# R7FA2A1AB register map
Vendor: Renesas; Series: RA2; File version: 1.1
CPU: CM23 r1p0, little endian, MPU, no FPU, VTOR, 2 interrupt priority bits
Registers are 8-bit, read-write, reset 0x0 unless marked. A register's access mark holds for its fields unless they carry their own. Offsets are from the block's base; [hi:lo] are bit positions.

## ACMPHS0 — High,Speed Analog Comparator 0
Base 0x40085000
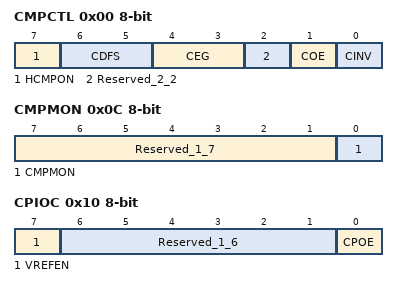
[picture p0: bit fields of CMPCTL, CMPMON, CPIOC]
0x00 CMPCTL — Comparator Control Register
  [7] HCMPON — Comparator operation control
  [6:5] CDFS — Noise filter selection
  [4:3] CEG — Selection of valid edge (Edge selector)
  [2] Reserved_2_2 — This bit is read as 0. The write value should be 0.
  [1] COE — Comparator output enable
  [0] CINV — Comparator output polarity selection
0x04 CMPSEL0 — Comparator Input Select Register
  [2:0] CMPSEL — Comparator input selection
0x08 CMPSEL1 — Comparator Reference Voltage Select Register
  [5:0] CRVS — Reference voltage selection
0x0C CMPMON ro — Comparator Output Monitor Register
  [7:1] Reserved_1_7 — These bits are read as 0000000.
  [0] CMPMON — Comparator output monitor
0x10 CPIOC — Comparator Output Control Register
  [7] VREFEN — Internal Vref enable
  [6:1] Reserved_1_6 — These bits are read as 000000. The write value should be 000000.
  [0] CPOE — Comparator output selection

## ACMPLP — Low,Power Analog Comparator
Base 0x40085E00
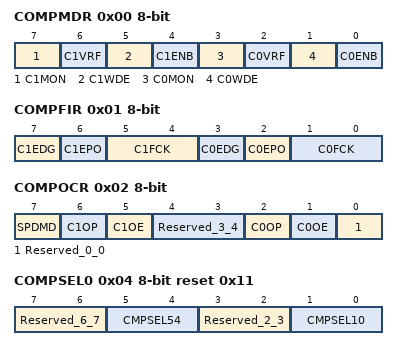
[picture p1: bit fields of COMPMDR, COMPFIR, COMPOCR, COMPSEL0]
0x00 COMPMDR — ACMPLP Mode Setting Register
  [7] C1MON — ACMPLP1 Monitor Flag
  [6] C1VRF — ACMPLP1 Reference Voltage SelectionNote1: It's effective only at the time of standard mode.IVREF0 and IVREF1 are chosen at window mode condition in spite of setting of this bit.
  [5] C1WDE — ACMPLP1 Window Function Mode Enable
  [4] C1ENB — ACMPLP1 Operation Enable
  [3] C0MON — ACMPLP0 Monitor Flag
  [2] C0VRF — ACMPLP0 Reference Voltage SelectionNote1: It's effective only at the time of standard mode.IVREF0 and IVREF1 are chosen at window mode condition in spite of setting of this bit.
  [1] C0WDE — ACMPLP0 Window Function Mode Enable
  [0] C0ENB — ACMPLP0 Operation Enable
0x01 COMPFIR — ACMPLP Filter Control Register
  [7] C1EDG — ACMPLP1 Filter Select
  [6] C1EPO — ACMPLP1 Edge Polarity Switching
  [5:4] C1FCK — ACMPLP1 Edge Detection Selection
  [3] C0EDG — ACMPLP0 Filter Select
  [2] C0EPO — ACMPLP0 Edge Polarity Switching
  [1:0] C0FCK — ACMPLP0 Edge Detection Selection
0x02 COMPOCR — ACMPLP Output Control Register
  [7] SPDMD — ACMPLP0/ACMPLP1 Speed Selection
  [6] C1OP — ACMPLP1 VCOUT Output Polarity Selection
  [5] C1OE — ACMPLP1 VCOUT Pin Output Enable
  [4:3] Reserved_3_4 — These bits are read as 00. The write value should be 00.
  [2] C0OP — ACMPLP0 VCOUT Output Polarity Selection
  [1] C0OE — ACMPLP0 VCOUT Pin Output Enable
  [0] Reserved_0_0 — This bit is read as 0. The write value should be 0.
0x04 COMPSEL0 reset 0x11 — Comparator Input Select Register
  [7:6] Reserved_6_7 — These bits are read as 00. The write value should be 00.
  [5:4] CMPSEL54 — ACMPLP1 Input (IVCMP1) Selection
  [3:2] Reserved_2_3 — These bits are read as 00. The write value should be 00.
  [1:0] CMPSEL10 — ACMPLP0 Input (IVCMP0) Selection
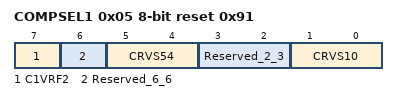
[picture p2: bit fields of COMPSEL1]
0x05 COMPSEL1 reset 0x91 — Comparator Reference voltage Select Register
  [7] C1VRF2 — ACMPLP1 Reference Voltage Selection
  [6] Reserved_6_6 — This bit is read as 0. The write value should be 0.
  [5:4] CRVS54 — ACMPLP1 Reference Voltage(IVREF1) Selection
  [3:2] Reserved_2_3 — These bits are read as 00. The write value should be 00.
  [1:0] CRVS10 — ACMPLP0 Reference Voltage (IVREF0) Selection

## TSN — Temperature Sensor
Base 0x407EC000
0x228 TSCDRL ro reset not defined — Temperature Sensor Calibration Data Register L
  [7:0] TSCDRL — The calibration data stores the lower 8 bits of the convertedvalue.
0x229 TSCDRH ro reset not defined — Temperature Sensor Calibration Data Register H
  [7:0] TSCDRH — The calibration data stores the higher 8 bits of the convertedvalue.

## DAC12 — 12-bit D/A converter
Base 0x4005E000
0x00 DADR0 16-bit — D/A Data Register 0
  [15:0] DADR — D/A Data RegisterNOTE: When DADPR.DPSEL = 0, the high,order 4 bits are fixed to 0: right justified format. When DADPR.DPSEL = 1, the low,order 4 bits are fixed to 0: left justified format.
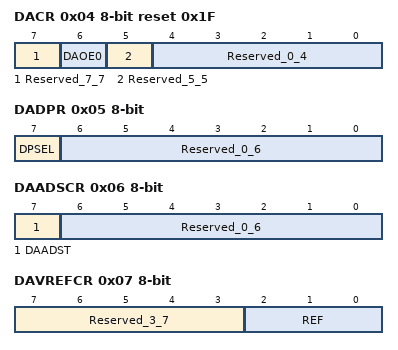
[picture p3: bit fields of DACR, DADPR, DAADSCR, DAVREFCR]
0x04 DACR reset 0x1F — D/A Control Register
  [7] Reserved_7_7 — This bit is read as 0. The write value should be 0.
  [6] DAOE0 — D/A Output Enable 0
  [5] Reserved_5_5 — This bit is read as 0. The write value should be 0.
  [4:0] Reserved_0_4 — These bits are read as 11111. The write value should be 11111.
0x05 DADPR — DADR0 Format Select Register
  [7] DPSEL — DADRm Format Select
  [6:0] Reserved_0_6 — These bits are read as 0000000. The write value should be 0000000.
0x06 DAADSCR — D/A,A/D Synchronous Start Control Register
  [7] DAADST — D/A,A/D Synchronous Conversion
  [6:0] Reserved_0_6 — These bits are read as 0000000. The write value should be 0000000.
0x07 DAVREFCR — D/A VREF Control Register
  [7:3] Reserved_3_7 — These bits are read as 00000. The write value should be 00000.
  [2:0] REF — D/A Reference Voltage Select
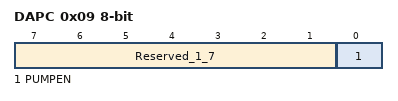
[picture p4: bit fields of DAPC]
0x09 DAPC — D/A Switch Charge Pump Control Register
  [7:1] Reserved_1_7 — These bits are read as 0000000. The write value should be 0000000.
  [0] PUMPEN — Charge Pump Enable
